# tviibe2m register map
Vendor: Infineon Technologies; Series: TVIIBE2M; File version: 1.0
CPU: CM4 r0p1, little endian, MPU, FPU, VTOR, 3 interrupt priority bits, 16 interrupts
Registers are 32-bit, read-write, reset 0x0 unless marked. A register's access mark holds for its fields unless they carry their own. Offsets are from the block's base; [hi:lo] are bit positions; lines under a group give offsets from that group; {n}, {i} and the like mark numbered series; 'fields as' and 'values as' point back to an identical list.

## GPIO — GPIO port control/configuration
Base 0x40310000
{0x0+0x80*i} PRT[{i}] (i=0..23) group — GPIO port registers
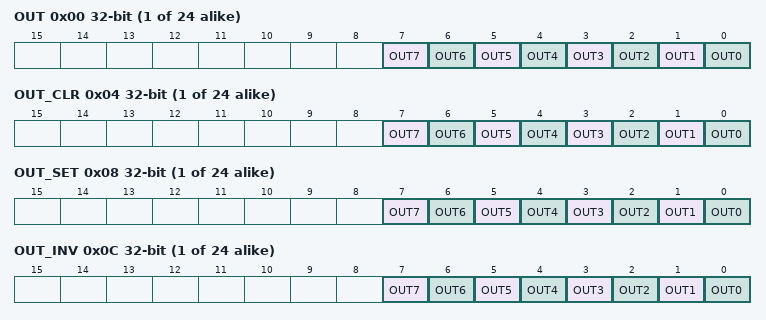
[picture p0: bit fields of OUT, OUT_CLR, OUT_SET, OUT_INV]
  0x00 OUT — Port output data register
    [n] OUT{n} (n=1..7) — IO output data for pin {n}
    [0] OUT0 — IO output data for pin 0 '0': Output state set to '0' '1': Output state set to '1'
  0x04 OUT_CLR — Port output data clear register
    [n] OUT{n} (n=1..7) — IO clear output for pin {n}
    [0] OUT0 — IO clear output for pin 0: '0': Output state not affected. '1': Output state set to '0'.
  0x08 OUT_SET — Port output data set register
    [n] OUT{n} (n=1..7) — IO set output for pin {n}
    [0] OUT0 — IO set output for pin 0: '0': Output state not affected. '1': Output state set to '1'.
  0x0C OUT_INV — Port output data invert register
    [n] OUT{n} (n=1..7) — IO invert output for pin {n}
    [0] OUT0 — IO invert output for pin 0: '0': Output state not affected. '1': Output state inverted ('0' => '1', '1' => '0').
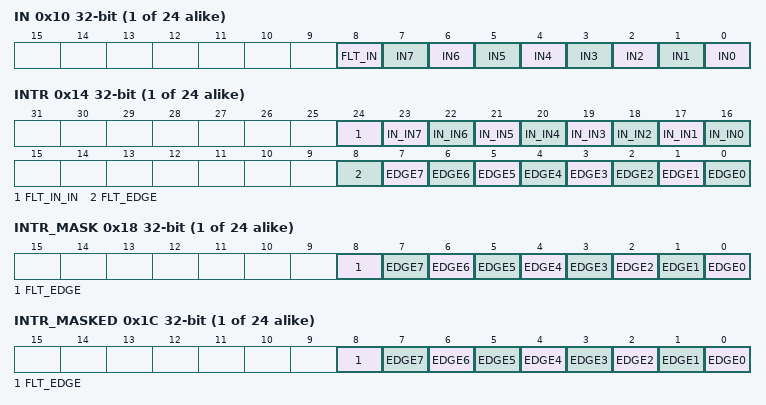
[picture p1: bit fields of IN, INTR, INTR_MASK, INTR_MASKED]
  0x10 IN ro — Port input state register
    [8] FLT_IN — Reads of this register return the logical state of the filtered pin as selected in the INTR_CFG.FLT_SEL register.
    [n] IN{n} (n=1..7) — IO pin state for pin {n}
    [0] IN0 — IO pin state for pin 0 '0': Low logic level present on pin. '1': High logic level present on pin. On reset assertion , IN register will get reset. The Pad value takes 2 clock cycles to be reflected into IN Register. It's value then depends on the external pin value.
  0x14 INTR — Port interrupt status register
    [24] FLT_IN_IN ro — Filtered pin state for pin selected by INTR_CFG.FLT_SEL
    [n+16] IN_IN{n} ro (n=0..7) — IO pin state for pin {n}
    [8] FLT_EDGE write-1-clears — Edge detected on filtered pin selected by INTR_CFG.FLT_SEL
    [n] EDGE{n} write-1-clears (n=1..7) — Edge detect for IO pin {n}
    [0] EDGE0 write-1-clears — Edge detect for IO pin 0 '0': No edge was detected on pin. '1': An edge was detected on pin.
  0x18 INTR_MASK — Port interrupt mask register
    [8] FLT_EDGE — Masks edge interrupt on filtered pin selected by INTR_CFG.FLT_SEL
    [n] EDGE{n} (n=1..7) — Masks edge interrupt on IO pin {n}
    [0] EDGE0 — Masks edge interrupt on IO pin 0 '0': Pin interrupt forwarding disabled '1': Pin interrupt forwarding enabled
  0x1C INTR_MASKED ro — Port interrupt masked status register
    [8] FLT_EDGE — Edge detected and masked on filtered pin selected by INTR_CFG.FLT_SEL
    [n] EDGE{n} (n=1..7) — Edge detected and masked on IO pin {n}
    [0] EDGE0 — Edge detected AND masked on IO pin 0 '0': Interrupt was not forwarded to CPU '1': Interrupt occurred and was forwarded to CPU
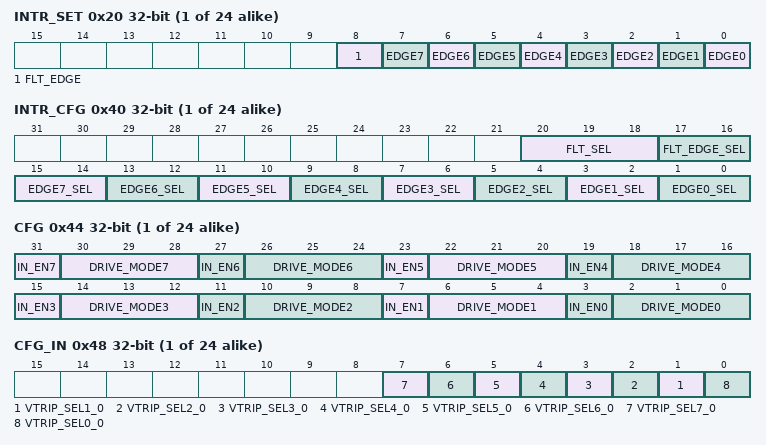
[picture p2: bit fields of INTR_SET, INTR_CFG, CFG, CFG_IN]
  0x20 INTR_SET — Port interrupt set register
    [8] FLT_EDGE write-1-sets — Sets edge detect interrupt for filtered pin selected by INTR_CFG.FLT_SEL
    [n] EDGE{n} write-1-sets (n=1..7) — Sets edge detect interrupt for IO pin {n}
    [0] EDGE0 write-1-sets — Sets edge detect interrupt for IO pin 0 '0': Interrupt state not affected '1': Interrupt set
  0x40 INTR_CFG — Port interrupt configuration register
    [20:18] FLT_SEL — Selects which pin is routed through the 50ns glitch filter to provide a glitch-safe interrupt.
    [17:16] FLT_EDGE_SEL — Sets which edge will trigger an IRQ for the glitch filtered pin (selected by INTR_CFG.FLT_SEL
      0=DISABLE (Disabled); 1=RISING (Rising edge); 2=FALLING (Falling edge); 3=BOTH (Both rising and falling edges)
    [2n+1:2n] EDGE{n}_SEL (n=1..7) — Sets which edge will trigger an IRQ for IO pin {n}
    [1:0] EDGE0_SEL — Sets which edge will trigger an IRQ for IO pin 0
      values as FLT_EDGE_SEL
  0x44 CFG — Port configuration register
    [4n+3] IN_EN{n} (n=1..7) — Enables the input buffer for IO pin {n}
    [4n+2:4n] DRIVE_MODE{n} (n=0..7) — The GPIO drive mode for IO pin {n}. Resistive pull-up and pull-down is selected in the drive mode. Note: when initializing IO's that are connected to a live bus (such as I2C), make sure the peripheral and HSIOM (HSIOM_PRT_SELx) is properly configured before turning the IO on here to avoid producing glitches on the bus. Note: that peripherals other than GPIO & UDB/DSI directly control both the output and output-enable of the output buffer (peripherals can drive strong 0 or strong 1 in any mode except OFF='0'). Note: D_OUT, D_OUT_EN are pins of GPIO cell.
      0=HIGHZ (Output buffer is off creating a high impedance input D_OUT = '0': High Impedance D_OUT = '1': High Impedance); 1=RSVD (N/A); 2=PULLUP (Resistive pull up); 3=PULLDOWN (Resistive pull down); 4=OD_DRIVESLOW (Open drain, drives low); 5=OD_DRIVESHIGH (Open drain, drives high); 6=STRONG (Strong D_OUTput buffer); 7=PULLUP_DOWN (Pull up or pull down)
    [3] IN_EN0 — Enables the input buffer for IO pin 0. This bit should be cleared when analog signals are present on the pin to avoid crowbar currents. The output buffer can be used to drive analog signals high or low without issue. '0': Input buffer disabled '1': Input buffer enabled
  0x48 CFG_IN — Port input buffer configuration register
    [n] VTRIP_SEL{n}_0 (n=1..7) — Configures the pin {n} input buffer mode (trip points and hysteresis)
    [0] VTRIP_SEL0_0 — Configures the pin 0 input buffer mode (trip points and hysteresis)
      0=CMOS (PSoC 6:: Input buffer compatible with CMOS and I2C interfaces Traveo II: Full encoding is shown in CFG_IN_AUTOLVL.VTRIP_SEL0_1); 1=TTL (PSoC 6:: Input buffer compatible with TTL and MediaLB interfaces Traveo II: full encoding is shown in CFG_IN_AUTOLVL.VTRIP_SEL0_1)
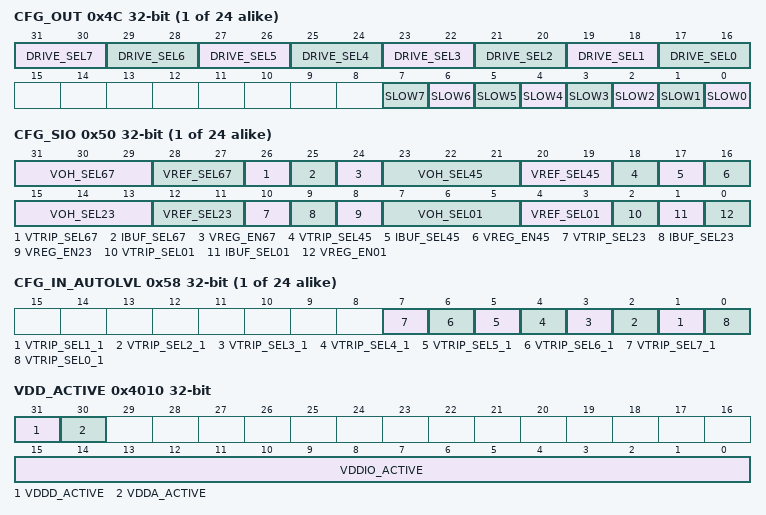
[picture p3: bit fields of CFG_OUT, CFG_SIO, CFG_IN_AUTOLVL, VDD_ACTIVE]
  0x4C CFG_OUT — Port output buffer configuration register
    [2n+17:2n+16] DRIVE_SEL{n} (n=1..7)
    [17:16] DRIVE_SEL0 — Documentation: Note: DRIVE_SELx are used among GPIO cells and HSIO_STD but the encoding values may differ as shown on the right side of this table
      0=DRIVE_SEL_ZERO (Please refer to architecture TRM section I/O System); 1=DRIVE_SEL_ONE (Please refer to architecture TRM section I/O System); 2=DRIVE_SEL_TWO (Please refer to architecture TRM section I/O System); 3=DRIVE_SEL_THREE (Please refer to architecture TRM section I/O System)
    [n] SLOW{n} (n=0..7)
  0x50 CFG_SIO — Port SIO configuration register
    [31:29] VOH_SEL67
    [28:27] VREF_SEL67
    [26] VTRIP_SEL67
    [25] IBUF_SEL67
    [24] VREG_EN67
    [23:21] VOH_SEL45
    [20:19] VREF_SEL45
    [18] VTRIP_SEL45
    [17] IBUF_SEL45
    [16] VREG_EN45
    [15:13] VOH_SEL23
    [12:11] VREF_SEL23
    [10] VTRIP_SEL23
    [9] IBUF_SEL23
    [8] VREG_EN23
    [7:5] VOH_SEL01 — Selects trip-point of input buffer. In single ended input buffer mode (IBUF01_SEL = '0'): 0: input buffer functions as a CMOS input buffer. 1: input buffer functions as a LVTTL input buffer. In differential input buffer mode (IBUF01_SEL = '1'): VTRIP_SEL=0: a) VREF_SEL=00, VOH_SEL=X -> Trip point=50 percent of vddio b) VREF_SEL=01, VOH_SEL=000 -> Trip point=Vohref (buffered) c) VREF_SEL=01, VOH_SEL=[1-7] -> Input buffer functions as CMOS input buffer. d) VREF_SEL=10/11, VOH_SEL=000 -> Trip point=Amuxbus_a/b (buffered) e) VREF_SEL=10/11, VOH_SEL=[1-7] -> Input buffer functions as CMOS input buffer. VTRIP_SEL=1: a) VREF_SEL=00, VOH_SEL=X -> Trip point=40 percent of vddio b) VREF_SEL=01, VOH_SEL=000 -> Trip point=0.5*Vohref c) VREF_SEL=01, VOH_SEL=[1-7] -> Input buffer functions as LVTTL input buffer. d) VREF_SEL=10/11, VOH_SEL=000 -> Trip point=0.5*Amuxbus_a/b (buffered) e) VREF_SEL=10/11, VOH_SEL=[1-7] -> Input buffer functions as LVTTL input buffer.
    [4:3] VREF_SEL01
    [2] VTRIP_SEL01
    [1] IBUF_SEL01
    [0] VREG_EN01 — The regulated output mode is selected ONLY if the CFG.DRIVE_MODE bits are set to the strong pull up (Z_1 = '5') mode If the CFG.DRIVE_MODE bits are set to any other mode the regulated output buffer will be disabled and the standard CMOS output buffer is used.
  0x58 CFG_IN_AUTOLVL — Port input buffer AUTOLVL configuration register
    [n] VTRIP_SEL{n}_1 (n=1..7) — Input buffer compatible with automotive (elevated Vil) interfaces.
    [0] VTRIP_SEL0_1 — Configures the input buffer mode (trip points and hysteresis) for GPIO upper bit. Lower bit is still selected by CFG_IN.VTRIP_SEL0_0 field. This field is used along with CFG_IN.VTRIP_SEL0_0 field as below: {CFG_IN_AUTOLVL.VTRIP_SEL0_1,CFG_IN.VTRIP_SEL0_0}: 0,0: CMOS 0,1: TTL 1,0: input buffer is compatible with automotive. 1,1: input buffer is compatible with automotvie
      0=CMOS_OR_TTL (Input buffer compatible with CMOS/TTL interfaces as described in CFG_IN.VTRIP_SEL0_0.); 1=AUTO (Input buffer compatible with AUTO (elevated Vil) interfaces when used along with CFG_IN.VTRIP_SEL0_0.)
0x4000 INTR_CAUSE0 ro — Interrupt port cause register 0
  [31:0] PORT_INT — Each IO port has an associated bit field in this register. The bit field reflects the IO port's interrupt line (bit field i reflects 'gpio_interrupts[i]' for IO port i). The register is used when the system uses a combined interrupt line 'gpio_interrupt'. The software ISR reads the register to determine which IO port(s) is responsible for the combined interrupt line. Once, the IO port(s) is determined, the IO port's GPIO_PRT_INTR register is read to determine the IO pin(s) in the IO port that caused the interrupt. '0': Port has no pending interrupt '1': Port has pending interrupt
{0x4000+4i} INTR_CAUSE{i} ro (i=1..3) — Interrupt port cause register {i}
  [31:0] PORT_INT — Each IO port has an associated bit field in this register. The bit field reflects the IO port's interrupt line (bit field i reflects 'gpio_interrupts[i]' for IO port i). The register is used when the system uses a combined interrupt line 'gpio_interrupt'. The software ISR reads the register to determine which IO port(s) is responsible for the combined interrupt line. Once, the IO port(s) is determined, the IO port's GPIO_PORT_INTR register is read to determine the IO pin(s) in the IO port that caused the interrupt. '0': Port has no pending interrupt '1': Port has pending interrupt
0x4010 VDD_ACTIVE ro — Extern power supply detection register
  [31] VDDD_ACTIVE — This bit indicates presence of the VDDD supply. This bit will always read-back 1. The VDDD supply has robust brown-out protection monitoring and it is not possible to read back this register without a valid supply. (This bit is used in certain test-modes to observe the brown-out detector status.)
  [30] VDDA_ACTIVE — Same as VDDIO_ACTIVE for the analog supply VDDA.
  [15:0] VDDIO_ACTIVE — Indicates presence or absence of VDDIO supplies (i.e. other than VDDD, VDDA) on the device (supplies are numbered 0..n-1). Note that VDDIO supplies have basic (crude) supply detectors only. If separate, robust, brown-out detection is desired on IO supplies, on-chip or off-chip analog resources need to provide it. For these bits to work reliable, the supply must be within valid spec range (per datasheet) or held at ground. Any in-between voltage has an undefined result. '0': Supply is not present '1': Supply is present When multiple VDDIO supplies are present, they will be assigned in alphanumeric ascending order to these bits during implementation. For example 'vddusb, vddio_0, vddio_a, vbackup, vddio_r, vddio_1' are present then they will be assigned to these bits as below: 0: vbackup, 1: vddio_0, 2: vddio_1, 3: vddio_a, 4: vddio_r, 5: vddusb'
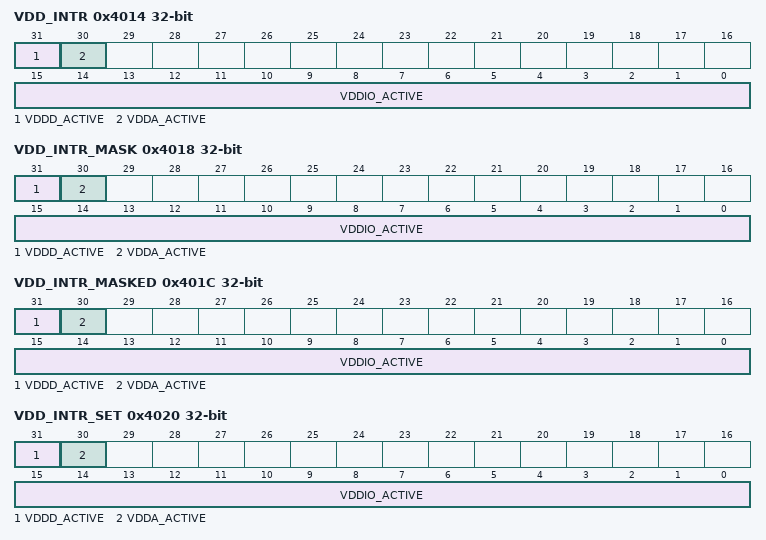
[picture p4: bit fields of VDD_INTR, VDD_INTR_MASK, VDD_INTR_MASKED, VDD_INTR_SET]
0x4014 VDD_INTR — Supply detection interrupt register
  [31] VDDD_ACTIVE write-1-clears — The VDDD supply is always present during operation so a supply transition can not occur. This bit will always read back '1'.
  [30] VDDA_ACTIVE write-1-clears — Same as VDDIO_ACTIVE for the analog supply VDDA.
  [15:0] VDDIO_ACTIVE write-1-clears — Supply state change detected. '0': No change to supply detected '1': Change to supply detected
0x4018 VDD_INTR_MASK — Supply detection interrupt mask register
  [31] VDDD_ACTIVE — Same as VDDIO_ACTIVE for the digital supply VDDD.
  [30] VDDA_ACTIVE — Same as VDDIO_ACTIVE for the analog supply VDDA.
  [15:0] VDDIO_ACTIVE — Masks supply interrupt on VDDIO. '0': VDDIO interrupt forwarding disabled '1': VDDIO interrupt forwarding enabled
0x401C VDD_INTR_MASKED ro — Supply detection interrupt masked register
  [31] VDDD_ACTIVE — Same as VDDIO_ACTIVE for the digital supply VDDD.
  [30] VDDA_ACTIVE — Same as VDDIO_ACTIVE for the analog supply VDDA.
  [15:0] VDDIO_ACTIVE — Supply transition detected AND masked '0': Interrupt was not forwarded to CPU '1': Interrupt occurred and was forwarded to CPU
0x4020 VDD_INTR_SET — Supply detection interrupt set register
  [31] VDDD_ACTIVE write-1-sets — Same as VDDIO_ACTIVE for the digital supply VDDD.
  [30] VDDA_ACTIVE write-1-sets — Same as VDDIO_ACTIVE for the analog supply VDDA.
  [15:0] VDDIO_ACTIVE write-1-sets — Sets supply interrupt. '0': Interrupt state not affected '1': Interrupt set

## Notices in the file
(c) 2016-2026, Infineon Technologies AG or an affiliate of
Infineon Technologies AG.
SPDX-License-Identifier: Apache-2.0
Licensed under the Apache License, Version 2.0 (the "License");
you may not use this file except in compliance with the License.
You may obtain a copy of the License at
http://www.apache.org/licenses/LICENSE-2.0
Unless required by applicable law or agreed to in writing, software
distributed under the License is distributed on an "AS IS" BASIS,
WITHOUT WARRANTIES OR CONDITIONS OF ANY KIND, either express or implied.
See the License for the specific language governing permissions and
limitations under the License.
